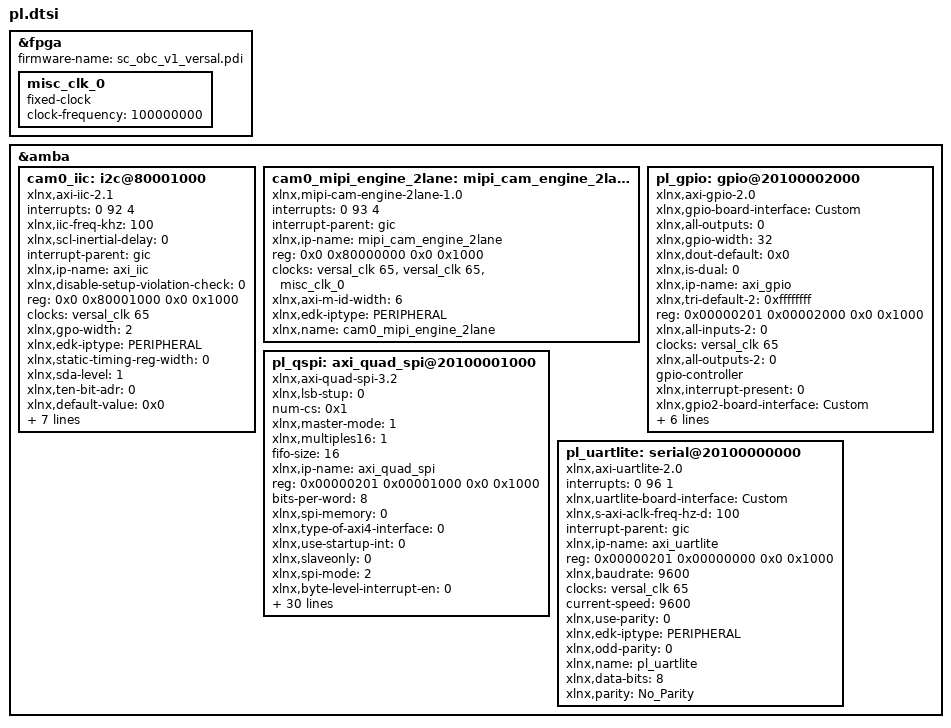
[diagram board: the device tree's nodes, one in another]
&fpga {
	firmware-name = "sc_obc_v1_versal.pdi";
	misc_clk_0: misc_clk_0 {
		compatible = "fixed-clock";
		clock-frequency = <100000000>;
		#clock-cells = <0>;
	};
};

&amba {
	cam0_iic: i2c@80001000 {
		interrupts = < 0 92 4 >;
		xlnx,iic-freq-khz = <100>;
		compatible = "xlnx,axi-iic-2.1" , "xlnx,xps-iic-2.00.a";
		xlnx,scl-inertial-delay = <0>;
		interrupt-parent = <&gic>;
		xlnx,ip-name = "axi_iic";
		xlnx,disable-setup-violation-check = <0>;
		reg = <0x0 0x80001000 0x0 0x1000>;
		clocks = <&versal_clk 65>;
		xlnx,gpo-width = <2>;
		xlnx,edk-iptype = "PERIPHERAL";
		xlnx,static-timing-reg-width = <0>;
		xlnx,sda-level = <1>;
		clock-names = "s_axi_aclk";
		xlnx,ten-bit-adr = <0>;
		xlnx,default-value = <0x0>;
		interrupt-names = "iic2intc_irpt";
		xlnx,iic-board-interface = "Custom";
		xlnx,timing-reg-width = <32>;
		xlnx,iic-freq = <100000>;
		xlnx,smbus-pmbus-host = <0>;
		xlnx,name = "cam0_iic";
		xlnx,axi-aclk-freq-mhz = <100>;
		xlnx,sda-inertial-delay = <0>;
	};
	cam0_mipi_engine_2lane: mipi_cam_engine_2lane@80000000 {
		compatible = "xlnx,mipi-cam-engine-2lane-1.0";
		interrupts = < 0 93 4 >;
		interrupt-parent = <&gic>;
		xlnx,ip-name = "mipi_cam_engine_2lane";
		reg = <0x0 0x80000000 0x0 0x1000>;
		clocks = <&versal_clk 65>, <&versal_clk 65>, <&misc_clk_0>;
		xlnx,axi-m-id-width = <6>;
		xlnx,edk-iptype = "PERIPHERAL";
		clock-names = "AXI_M_CLK" , "AXI_S_CLK" , "MIPI_CLK";
		interrupt-names = "MIPI_INT";
		xlnx,name = "cam0_mipi_engine_2lane";
	};
	pl_gpio: gpio@20100002000 {
		xlnx,gpio-board-interface = "Custom";
		compatible = "xlnx,axi-gpio-2.0" , "xlnx,xps-gpio-1.00.a";
		xlnx,all-outputs = <0>;
		#gpio-cells = <2>;
		xlnx,gpio-width = <32>;
		xlnx,dout-default = <0x0>;
		xlnx,is-dual = <0>;
		xlnx,ip-name = "axi_gpio";
		xlnx,tri-default-2 = <0xffffffff>;
		reg = <0x00000201 0x00002000 0x0 0x1000>;
		xlnx,all-inputs-2 = <0>;
		clocks = <&versal_clk 65>;
		xlnx,all-outputs-2 = <0>;
		gpio-controller;
		xlnx,interrupt-present = <0>;
		xlnx,gpio2-board-interface = "Custom";
		xlnx,edk-iptype = "PERIPHERAL";
		xlnx,dout-default-2 = <0x0>;
		xlnx,gpio2-width = <32>;
		clock-names = "s_axi_aclk";
		xlnx,tri-default = <0xffffffff>;
		xlnx,name = "pl_gpio";
		xlnx,all-inputs = <0>;
	};
	pl_qspi: axi_quad_spi@20100001000 {
		xlnx,lsb-stup = <0>;
		num-cs = <0x1>;
		xlnx,master-mode = <1>;
		xlnx,multiples16 = <1>;
		fifo-size = <16>;
		xlnx,ip-name = "axi_quad_spi";
		reg = <0x00000201 0x00001000 0x0 0x1000>;
		bits-per-word = <8>;
		xlnx,spi-memory = <0>;
		xlnx,type-of-axi4-interface = <0>;
		xlnx,use-startup-int = <0>;
		xlnx,slaveonly = <0>;
		xlnx,spi-mode = <2>;
		interrupt-names = "ip2intc_irpt";
		compatible = "xlnx,axi-quad-spi-3.2" , "xlnx,xps-spi-2.00.a";
		xlnx,byte-level-interrupt-en = <0>;
		xlnx,s-axi4-addr-width = <24>;
		xlnx,sck-ratio = <2>;
		interrupt-parent = <&gic>;
		xlnx,async-clk = <1>;
		xlnx,sck-ratio1 = <1>;
		xlnx,name = "pl_qspi";
		xlnx,fifo-included = <1>;
		interrupts = < 0 97 1 >;
		xlnx,use-startup-ext = <0>;
		xlnx,hasfifos = <1>;
		xlnx,s-axi4-id-width = <4>;
		xlnx,shared-startup = <0>;
		xlnx,new-seq-en = <1>;
		xlnx,qspi-board-interface = "Custom";
		clocks = <&versal_clk 66>, <&versal_clk 65>;
		xlnx,edk-iptype = "PERIPHERAL";
		xlnx,fifo-depth = <16>;
		clock-names = "ext_spi_clk" , "s_axi_aclk";
		xlnx,axi-interface = <0>;
		xlnx,num-ss-bits = <0x1>;
		xlnx,select-xpm = <0>;
		xlnx,xip-mode = <0>;
		xlnx,xip-perf-mode = <1>;
		xlnx,dual-quad-mode = <0>;
		xlnx,num-transfer-bits = <8>;
		xlnx,s-axi4-data-width = <32>;
		xlnx,use-startup = <0>;
		xlnx,spi-mem-addr-bits = <24>;
		xlnx,uc-family = <0>;
		xlnx,sub-family = "versal";
		xlnx,Axi4-address = <0>;
	};
	pl_uartlite: serial@20100000000 {
		interrupts = < 0 96 1 >;
		compatible = "xlnx,axi-uartlite-2.0" , "xlnx,xps-uartlite-1.00.a";
		xlnx,uartlite-board-interface = "Custom";
		xlnx,s-axi-aclk-freq-hz-d = <100>;
		interrupt-parent = <&gic>;
		xlnx,ip-name = "axi_uartlite";
		reg = <0x00000201 0x00000000 0x0 0x1000>;
		xlnx,baudrate = <9600>;
		clocks = <&versal_clk 65>;
		current-speed = <9600>;
		xlnx,use-parity = <0>;
		xlnx,edk-iptype = "PERIPHERAL";
		xlnx,odd-parity = <0>;
		clock-names = "s_axi_aclk";
		interrupt-names = "interrupt";
		xlnx,name = "pl_uartlite";
		xlnx,data-bits = <8>;
		xlnx,parity = "No_Parity";
	};
};
